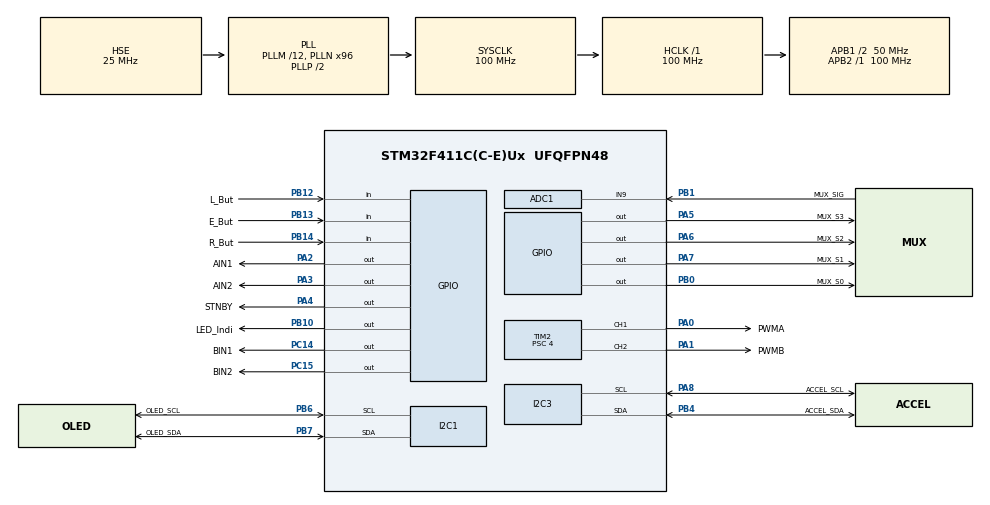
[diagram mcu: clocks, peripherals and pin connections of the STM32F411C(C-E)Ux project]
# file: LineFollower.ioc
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ADC1.Channel-0\#ChannelRegularConversion=ADC_CHANNEL_9
ADC1.NbrOfConversionFlag=1
ADC1.Rank-0\#ChannelRegularConversion=1
ADC1.SamplingTime-0\#ChannelRegularConversion=ADC_SAMPLETIME_56CYCLES
ADC1.master=1
I2C3.I2C_Mode=I2C_Fast
Mcu.Family=STM32F4
Mcu.Name=STM32F411C(C-E)Ux
Mcu.Package=UFQFPN48
NVIC.PriorityGroup=NVIC_PRIORITYGROUP_4
PA0-WKUP.GPIO_Label=PWMA
PA0-WKUP.Signal=S_TIM2_CH1_ETR
PA1.GPIO_Label=PWMB
PA1.Signal=S_TIM2_CH2
PA2.GPIO_Label=AIN1
PA2.Signal=GPIO_Output
PA3.GPIO_Label=AIN2
PA3.Signal=GPIO_Output
PA4.GPIO_Label=STNBY
PA4.Signal=GPIO_Output
PA5.GPIO_Label=MUX_S3
PA5.Signal=GPIO_Output
PA6.GPIO_Label=MUX_S2
PA6.Signal=GPIO_Output
PA7.GPIO_Label=MUX_S1
PA7.Signal=GPIO_Output
PA8.GPIO_Label=ACCEL_SCL
PA8.Mode=I2C
PA8.Signal=I2C3_SCL
PB0.GPIO_Label=MUX_S0
PB0.Signal=GPIO_Output
PB1.GPIO_Label=MUX_SIG
PB1.Signal=ADCx_IN9
PB10.GPIO_Label=LED_Indi
PB10.Signal=GPIO_Output
PB12.GPIO_Label=L_But
PB12.GPIO_PuPd=GPIO_PULLUP
PB12.Signal=GPIO_Input
PB13.GPIO_Label=E_But
PB13.GPIO_PuPd=GPIO_PULLUP
PB13.Signal=GPIO_Input
PB14.GPIO_Label=R_But
PB14.GPIO_PuPd=GPIO_PULLUP
PB14.Signal=GPIO_Input
PB4.GPIO_Label=ACCEL_SDA
PB4.Mode=I2C
PB4.Signal=I2C3_SDA
PB6.GPIO_Label=OLED_SCL
PB6.Mode=I2C
PB6.Signal=I2C1_SCL
PB7.GPIO_Label=OLED_SDA
PB7.Mode=I2C
PB7.Signal=I2C1_SDA
PC14-OSC32_IN.GPIO_Label=BIN1
PC14-OSC32_IN.Signal=GPIO_Output
PC15-OSC32_OUT.GPIO_Label=BIN2
PC15-OSC32_OUT.Signal=GPIO_Output
PH0\ -\ OSC_IN.Mode=HSE-External-Oscillator
PH0\ -\ OSC_IN.Signal=RCC_OSC_IN
PH1\ -\ OSC_OUT.Mode=HSE-External-Oscillator
PH1\ -\ OSC_OUT.Signal=RCC_OSC_OUT
ProjectManager.HeapSize=0x200
ProjectManager.StackSize=0x400
ProjectManager.TargetToolchain=CMake
RCC.48MHZClocksFreq_Value=50000000
RCC.AHBFreq_Value=100000000
RCC.APB1CLKDivider=RCC_HCLK_DIV2
RCC.APB1Freq_Value=50000000
RCC.APB1TimFreq_Value=100000000
RCC.APB2Freq_Value=100000000
RCC.APB2TimFreq_Value=100000000
RCC.CortexFreq_Value=100000000
RCC.HCLKFreq_Value=100000000
RCC.HSE_VALUE=25000000
RCC.HSI_VALUE=16000000
RCC.LSE_VALUE=32768
RCC.PLLM=12
RCC.PLLN=96
RCC.PLLSourceVirtual=RCC_PLLSOURCE_HSE
RCC.SYSCLKFreq_VALUE=100000000
RCC.SYSCLKSource=RCC_SYSCLKSOURCE_PLLCLK
RCC.VCOOutputFreq_Value=200000000
SH.ADCx_IN9.0=ADC1_IN9,IN9
SH.S_TIM2_CH1_ETR.0=TIM2_CH1,PWM Generation1 CH1
SH.S_TIM2_CH2.0=TIM2_CH2,PWM Generation2 CH2
TIM2.Channel-PWM\ Generation1\ CH1=TIM_CHANNEL_1
TIM2.Channel-PWM\ Generation2\ CH2=TIM_CHANNEL_2
TIM2.Period=999
TIM2.Prescaler=4
board=custom

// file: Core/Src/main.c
/* USER CODE BEGIN Header */
/**
 ******************************************************************************
 * @file           : main.c
 * @brief          : Main program body
 ******************************************************************************
 * @attention
 *
 * Copyright (c) 2026 STMicroelectronics.
 * All rights reserved.
 *
 * This software is licensed under terms that can be found in the LICENSE file
 * in the root directory of this software component.
 * If no LICENSE file comes with this software, it is provided AS-IS.
 *
 ******************************************************************************
 */
/* USER CODE END Header */
#include "main.h"

/* USER CODE BEGIN Includes */
#include "menu.h"

/* USER CODE END Includes */

ADC_HandleTypeDef hadc1;

I2C_HandleTypeDef hi2c1;
I2C_HandleTypeDef hi2c3;

TIM_HandleTypeDef htim2;

void SystemClock_Config(void);
static void MX_GPIO_Init(void);
static void MX_ADC1_Init(void);
static void MX_I2C1_Init(void);
static void MX_I2C3_Init(void);
static void MX_TIM2_Init(void);

int main(void) {

  /* MCU Configuration--------------------------------------------------------*/

  /* Reset of all peripherals, Initializes the Flash interface and the Systick.
   */
  HAL_Init();

  /* Configure the system clock */
  SystemClock_Config();

  /* Initialize all configured peripherals */
  MX_GPIO_Init();
  MX_ADC1_Init();
  MX_I2C1_Init();
  MX_I2C3_Init();
  MX_TIM2_Init();
  /* USER CODE BEGIN 2 */
  App_Init();
  /* USER CODE END 2 */

  /* Infinite loop */
  while (1) {

    /* USER CODE BEGIN 3 */
    App_Update();
  }
  /* USER CODE END 3 */
}

void SystemClock_Config(void) {
  RCC_OscInitTypeDef RCC_OscInitStruct = {0};
  RCC_ClkInitTypeDef RCC_ClkInitStruct = {0};

  /** Configure the main internal regulator output voltage
   */
  __HAL_RCC_PWR_CLK_ENABLE();
  __HAL_PWR_VOLTAGESCALING_CONFIG(PWR_REGULATOR_VOLTAGE_SCALE1);

  /** Initializes the RCC Oscillators according to the specified parameters
   * in the RCC_OscInitTypeDef structure.
   */
  RCC_OscInitStruct.OscillatorType = RCC_OSCILLATORTYPE_HSE;
  RCC_OscInitStruct.HSEState = RCC_HSE_ON;
  RCC_OscInitStruct.PLL.PLLState = RCC_PLL_ON;
  RCC_OscInitStruct.PLL.PLLSource = RCC_PLLSOURCE_HSE;
  RCC_OscInitStruct.PLL.PLLM = 12;
  RCC_OscInitStruct.PLL.PLLN = 96;
  RCC_OscInitStruct.PLL.PLLP = RCC_PLLP_DIV2;
  RCC_OscInitStruct.PLL.PLLQ = 4;
  if (HAL_RCC_OscConfig(&RCC_OscInitStruct) != HAL_OK) {
    Error_Handler();
  }

  /** Initializes the CPU, AHB and APB buses clocks
   */
  RCC_ClkInitStruct.ClockType = RCC_CLOCKTYPE_HCLK | RCC_CLOCKTYPE_SYSCLK |
                                RCC_CLOCKTYPE_PCLK1 | RCC_CLOCKTYPE_PCLK2;
  RCC_ClkInitStruct.SYSCLKSource = RCC_SYSCLKSOURCE_PLLCLK;
  RCC_ClkInitStruct.AHBCLKDivider = RCC_SYSCLK_DIV1;
  RCC_ClkInitStruct.APB1CLKDivider = RCC_HCLK_DIV2;
  RCC_ClkInitStruct.APB2CLKDivider = RCC_HCLK_DIV1;

  if (HAL_RCC_ClockConfig(&RCC_ClkInitStruct, FLASH_LATENCY_3) != HAL_OK) {
    Error_Handler();
  }
}

static void MX_ADC1_Init(void) {

  ADC_ChannelConfTypeDef sConfig = {0};

  /** Configure the global features of the ADC (Clock, Resolution, Data
   * Alignment and number of conversion)
   */
  hadc1.Instance = ADC1;
  hadc1.Init.ClockPrescaler = ADC_CLOCK_SYNC_PCLK_DIV4;
  hadc1.Init.Resolution = ADC_RESOLUTION_12B;
  hadc1.Init.ScanConvMode = DISABLE;
  hadc1.Init.ContinuousConvMode = DISABLE;
  hadc1.Init.DiscontinuousConvMode = DISABLE;
  hadc1.Init.ExternalTrigConvEdge = ADC_EXTERNALTRIGCONVEDGE_NONE;
  hadc1.Init.ExternalTrigConv = ADC_SOFTWARE_START;
  hadc1.Init.DataAlign = ADC_DATAALIGN_RIGHT;
  hadc1.Init.NbrOfConversion = 1;
  hadc1.Init.DMAContinuousRequests = DISABLE;
  hadc1.Init.EOCSelection = ADC_EOC_SINGLE_CONV;
  if (HAL_ADC_Init(&hadc1) != HAL_OK) {
    Error_Handler();
  }

  /** Configure for the selected ADC regular channel its corresponding rank in
   * the sequencer and its sample time.
   */
  sConfig.Channel = ADC_CHANNEL_9;
  sConfig.Rank = 1;
  sConfig.SamplingTime =
      ADC_SAMPLETIME_480CYCLES; /* QRE1113 phototransistor has high output
                                   impedance (~10-100 kΩ); 480 cycles = 20 µs at
                                   24 MHz ADC clock gives the sample-hold
                                   capacitor enough time to charge through the
                                   MUX ON-resistance. */
  if (HAL_ADC_ConfigChannel(&hadc1, &sConfig) != HAL_OK) {
    Error_Handler();
  }
}

static void MX_I2C1_Init(void) {

  hi2c1.Instance = I2C1;
  hi2c1.Init.ClockSpeed = 400000; /* Fast-mode 400 kHz (was 100 kHz) */
  hi2c1.Init.DutyCycle = I2C_DUTYCYCLE_2;
  hi2c1.Init.OwnAddress1 = 0;
  hi2c1.Init.AddressingMode = I2C_ADDRESSINGMODE_7BIT;
  hi2c1.Init.DualAddressMode = I2C_DUALADDRESS_DISABLE;
  hi2c1.Init.OwnAddress2 = 0;
  hi2c1.Init.GeneralCallMode = I2C_GENERALCALL_DISABLE;
  hi2c1.Init.NoStretchMode = I2C_NOSTRETCH_DISABLE;
  if (HAL_I2C_Init(&hi2c1) != HAL_OK) {
    Error_Handler();
  }
}

static void MX_I2C3_Init(void) {

  hi2c3.Instance = I2C3;
  hi2c3.Init.ClockSpeed = 400000;
  hi2c3.Init.DutyCycle = I2C_DUTYCYCLE_2;
  hi2c3.Init.OwnAddress1 = 0;
  hi2c3.Init.AddressingMode = I2C_ADDRESSINGMODE_7BIT;
  hi2c3.Init.DualAddressMode = I2C_DUALADDRESS_DISABLE;
  hi2c3.Init.OwnAddress2 = 0;
  hi2c3.Init.GeneralCallMode = I2C_GENERALCALL_DISABLE;
  hi2c3.Init.NoStretchMode = I2C_NOSTRETCH_DISABLE;
  if (HAL_I2C_Init(&hi2c3) != HAL_OK) {
    Error_Handler();
  }
}

static void MX_TIM2_Init(void) {

  TIM_MasterConfigTypeDef sMasterConfig = {0};
  TIM_OC_InitTypeDef sConfigOC = {0};

  htim2.Instance = TIM2;
  htim2.Init.Prescaler = 4; /* 100MHz / 5 = 20MHz timer clock      */
  htim2.Init.CounterMode = TIM_COUNTERMODE_UP;
  htim2.Init.Period = 999; /* 20MHz / 1000 = 20kHz PWM, 1000 steps */
  htim2.Init.ClockDivision = TIM_CLOCKDIVISION_DIV1;
  htim2.Init.AutoReloadPreload = TIM_AUTORELOAD_PRELOAD_DISABLE;
  if (HAL_TIM_PWM_Init(&htim2) != HAL_OK) {
    Error_Handler();
  }
  sMasterConfig.MasterOutputTrigger = TIM_TRGO_RESET;
  sMasterConfig.MasterSlaveMode = TIM_MASTERSLAVEMODE_DISABLE;
  if (HAL_TIMEx_MasterConfigSynchronization(&htim2, &sMasterConfig) != HAL_OK) {
    Error_Handler();
  }
  sConfigOC.OCMode = TIM_OCMODE_PWM1;
  sConfigOC.Pulse = 0;
  sConfigOC.OCPolarity = TIM_OCPOLARITY_HIGH;
  sConfigOC.OCFastMode = TIM_OCFAST_DISABLE;
  if (HAL_TIM_PWM_ConfigChannel(&htim2, &sConfigOC, TIM_CHANNEL_1) != HAL_OK) {
    Error_Handler();
  }
  if (HAL_TIM_PWM_ConfigChannel(&htim2, &sConfigOC, TIM_CHANNEL_2) != HAL_OK) {
    Error_Handler();
  }
  HAL_TIM_MspPostInit(&htim2);
}

static void MX_GPIO_Init(void) {
  GPIO_InitTypeDef GPIO_InitStruct = {0};

  /* GPIO Ports Clock Enable */
  __HAL_RCC_GPIOC_CLK_ENABLE();
  __HAL_RCC_GPIOH_CLK_ENABLE();
  __HAL_RCC_GPIOA_CLK_ENABLE();
  __HAL_RCC_GPIOB_CLK_ENABLE();

  /*Configure GPIO pin Output Level */
  HAL_GPIO_WritePin(GPIOC, BIN1_Pin | BIN2_Pin, GPIO_PIN_RESET);

  /*Configure GPIO pin Output Level */
  HAL_GPIO_WritePin(GPIOA, AIN1_Pin | AIN2_Pin | STNBY_Pin, GPIO_PIN_RESET);

  /*Configure GPIO pin Output Level */
  HAL_GPIO_WritePin(GPIOB, LED_Indi_Pin, GPIO_PIN_RESET);

  /*Configure GPIO pins : BIN1_Pin BIN2_Pin */
  GPIO_InitStruct.Pin = BIN1_Pin | BIN2_Pin;
  GPIO_InitStruct.Mode = GPIO_MODE_OUTPUT_PP;
  GPIO_InitStruct.Pull = GPIO_NOPULL;
  GPIO_InitStruct.Speed = GPIO_SPEED_FREQ_LOW;
  HAL_GPIO_Init(GPIOC, &GPIO_InitStruct);

  /*Configure GPIO pins : AIN1_Pin AIN2_Pin STNBY_Pin */
  GPIO_InitStruct.Pin = AIN1_Pin | AIN2_Pin | STNBY_Pin;
  GPIO_InitStruct.Mode = GPIO_MODE_OUTPUT_PP;
  GPIO_InitStruct.Pull = GPIO_NOPULL;
  GPIO_InitStruct.Speed = GPIO_SPEED_FREQ_LOW;
  HAL_GPIO_Init(GPIOA, &GPIO_InitStruct);

  /*Configure GPIO pin : LED_Indi_Pin */
  GPIO_InitStruct.Pin = LED_Indi_Pin;
  GPIO_InitStruct.Mode = GPIO_MODE_OUTPUT_PP;
  GPIO_InitStruct.Pull = GPIO_NOPULL;
  GPIO_InitStruct.Speed = GPIO_SPEED_FREQ_LOW;
  HAL_GPIO_Init(GPIOB, &GPIO_InitStruct);

  /*Configure GPIO pins : MUX_S3_Pin MUX_S2_Pin MUX_S1_Pin (GPIOA outputs) */
  HAL_GPIO_WritePin(GPIOA, MUX_S3_Pin | MUX_S2_Pin | MUX_S1_Pin,
                    GPIO_PIN_RESET);
  GPIO_InitStruct.Pin = MUX_S3_Pin | MUX_S2_Pin | MUX_S1_Pin;
  GPIO_InitStruct.Mode = GPIO_MODE_OUTPUT_PP;
  GPIO_InitStruct.Pull = GPIO_NOPULL;
  GPIO_InitStruct.Speed = GPIO_SPEED_FREQ_HIGH;
  HAL_GPIO_Init(GPIOA, &GPIO_InitStruct);

  /*Configure GPIO pin : MUX_S0_Pin (PB0, GPIOB output) */
  HAL_GPIO_WritePin(MUX_S0_GPIO_Port, MUX_S0_Pin, GPIO_PIN_RESET);
  GPIO_InitStruct.Pin = MUX_S0_Pin;
  GPIO_InitStruct.Mode = GPIO_MODE_OUTPUT_PP;
  GPIO_InitStruct.Pull = GPIO_NOPULL;
  GPIO_InitStruct.Speed = GPIO_SPEED_FREQ_HIGH;
  HAL_GPIO_Init(MUX_S0_GPIO_Port, &GPIO_InitStruct);
  /* PB1 (MUX SIG) is configured as analog by HAL_ADC_MspInit — no GPIO init
   * here */

  /*Configure GPIO pins : L_But_Pin E_But_Pin R_But_Pin */
  GPIO_InitStruct.Pin = L_But_Pin | E_But_Pin | R_But_Pin;
  GPIO_InitStruct.Mode = GPIO_MODE_INPUT;
  GPIO_InitStruct.Pull = GPIO_PULLUP;
  HAL_GPIO_Init(GPIOB, &GPIO_InitStruct);

}

void Error_Handler(void) {
  __disable_irq();
  while (1) {
  }
}
#ifdef USE_FULL_ASSERT
/**
 * @brief  Reports the name of the source file and the source line number
 *         where the assert_param error has occurred.
 * @param  file: pointer to the source file name
 * @param  line: assert_param error line source number
 * @retval None
 */
void assert_failed(uint8_t *file, uint32_t line) {
  /* USER CODE BEGIN 6 */
  /* User can add his own implementation to report the file name and line
     number, ex: printf("Wrong parameters value: file %s on line %d\r\n", file,
     line) */
  /* USER CODE END 6 */
}
#endif /* USE_FULL_ASSERT */
